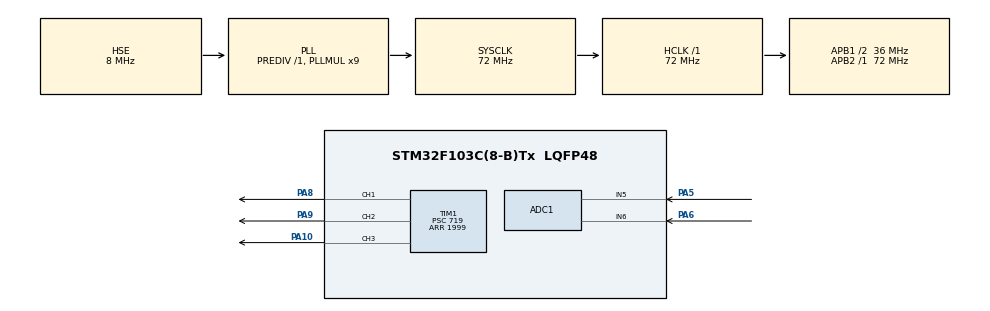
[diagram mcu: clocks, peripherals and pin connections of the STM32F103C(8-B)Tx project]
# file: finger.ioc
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ADC1.Channel-0\#ChannelRegularConversion=ADC_CHANNEL_5
ADC1.Channel-1\#ChannelRegularConversion=ADC_CHANNEL_6
ADC1.ContinuousConvMode=ENABLE
ADC1.NbrOfConversion=2
ADC1.NbrOfConversionFlag=1
ADC1.Rank-0\#ChannelRegularConversion=1
ADC1.Rank-1\#ChannelRegularConversion=2
ADC1.SamplingTime-0\#ChannelRegularConversion=ADC_SAMPLETIME_13CYCLES_5
ADC1.SamplingTime-1\#ChannelRegularConversion=ADC_SAMPLETIME_13CYCLES_5
ADC1.master=1
Dma.ADC1.0.Direction=DMA_PERIPH_TO_MEMORY
Dma.ADC1.0.Instance=DMA1_Channel1
Dma.ADC1.0.MemDataAlignment=DMA_MDATAALIGN_HALFWORD
Dma.ADC1.0.MemInc=DMA_MINC_ENABLE
Dma.ADC1.0.Mode=DMA_CIRCULAR
Dma.ADC1.0.PeriphDataAlignment=DMA_PDATAALIGN_HALFWORD
Dma.ADC1.0.PeriphInc=DMA_PINC_DISABLE
Dma.ADC1.0.Priority=DMA_PRIORITY_LOW
Dma.Request0=ADC1
Mcu.Family=STM32F1
Mcu.Name=STM32F103C(8-B)Tx
Mcu.Package=LQFP48
NVIC.DMA1_Channel1_IRQn=true\:0\:0\:false\:false\:true\:false\:true\:true
NVIC.PriorityGroup=NVIC_PRIORITYGROUP_4
PA10.Signal=S_TIM1_CH3
PA13.Mode=Serial_Wire
PA13.Signal=SYS_JTMS-SWDIO
PA14.Mode=Serial_Wire
PA14.Signal=SYS_JTCK-SWCLK
PA5.Signal=ADCx_IN5
PA6.Signal=ADCx_IN6
PA8.Signal=S_TIM1_CH1
PA9.Signal=S_TIM1_CH2
PC14-OSC32_IN.Mode=LSE-External-Oscillator
PC14-OSC32_IN.Signal=RCC_OSC32_IN
PC15-OSC32_OUT.Mode=LSE-External-Oscillator
PC15-OSC32_OUT.Signal=RCC_OSC32_OUT
PD0-OSC_IN.Mode=HSE-External-Oscillator
PD0-OSC_IN.Signal=RCC_OSC_IN
PD1-OSC_OUT.Mode=HSE-External-Oscillator
PD1-OSC_OUT.Signal=RCC_OSC_OUT
ProjectManager.HeapSize=0x200
ProjectManager.StackSize=0x400
ProjectManager.TargetToolchain=STM32CubeIDE
RCC.ADCPresc=RCC_ADCPCLK2_DIV6
RCC.AHBFreq_Value=72000000
RCC.APB1CLKDivider=RCC_HCLK_DIV2
RCC.APB1Freq_Value=36000000
RCC.APB1TimFreq_Value=72000000
RCC.APB2Freq_Value=72000000
RCC.APB2TimFreq_Value=72000000
RCC.HCLKFreq_Value=72000000
RCC.PLLMUL=RCC_PLL_MUL9
RCC.PLLSourceVirtual=RCC_PLLSOURCE_HSE
RCC.SYSCLKFreq_VALUE=72000000
RCC.SYSCLKSource=RCC_SYSCLKSOURCE_PLLCLK
RCC.USBFreq_Value=72000000
SH.ADCx_IN5.0=ADC1_IN5,IN5
SH.ADCx_IN6.0=ADC1_IN6,IN6
SH.S_TIM1_CH1.0=TIM1_CH1,PWM Generation1 CH1
SH.S_TIM1_CH2.0=TIM1_CH2,PWM Generation2 CH2
SH.S_TIM1_CH3.0=TIM1_CH3,PWM Generation3 CH3
TIM1.Channel-PWM\ Generation1\ CH1=TIM_CHANNEL_1
TIM1.Channel-PWM\ Generation2\ CH2=TIM_CHANNEL_2
TIM1.Channel-PWM\ Generation3\ CH3=TIM_CHANNEL_3
TIM1.Period=1999
TIM1.Prescaler=719
board=custom

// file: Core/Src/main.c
/* USER CODE BEGIN Header */
/**
  ******************************************************************************
  * @file           : main.c
  * @brief          : Main program body
  ******************************************************************************
  * @attention
  *
  * Copyright (c) 2025 STMicroelectronics.
  * All rights reserved.
  *
  * This software is licensed under terms that can be found in the LICENSE file
  * in the root directory of this software component.
  * If no LICENSE file comes with this software, it is provided AS-IS.
  *
  ******************************************************************************
  */
/* USER CODE END Header */
#include "main.h"
#include "adc.h"
#include "dma.h"
#include "tim.h"
#include "gpio.h"

/* USER CODE BEGIN Includes */
#include "servo.h"
#include "adc_to_duty.h"
#include "stdint.h"
/* USER CODE END Includes */

/* USER CODE BEGIN PV */
extern TIM_HandleTypeDef htim1;
uint16_t values[2];
int d1=0, d2=0;
/* USER CODE END PV */

void SystemClock_Config(void);

int main(void)
{

  /* MCU Configuration--------------------------------------------------------*/

  /* Reset of all peripherals, Initializes the Flash interface and the Systick. */
  HAL_Init();

  /* Configure the system clock */
  SystemClock_Config();

  /* Initialize all configured peripherals */
  MX_GPIO_Init();
  MX_DMA_Init();
  MX_TIM1_Init();
  MX_ADC1_Init();
  /* USER CODE BEGIN 2 */
  HAL_TIM_PWM_Start(&htim1, TIM_CHANNEL_ALL);

  HAL_ADCEx_Calibration_Start(&hadc1);
  HAL_ADC_Start_DMA(&hadc1, (uint32_t*)values, sizeof(values)/sizeof(uint16_t));

  /* USER CODE END 2 */

  /* Infinite loop */
  /* USER CODE BEGIN WHILE */
  while (1)
  {
	  d1 = Transform(values[0]);
	  d2 = Transform(values[1]);
	  Load(d1, d2);
    /* USER CODE END WHILE */

  }
}

void SystemClock_Config(void)
{
  RCC_OscInitTypeDef RCC_OscInitStruct = {0};
  RCC_ClkInitTypeDef RCC_ClkInitStruct = {0};
  RCC_PeriphCLKInitTypeDef PeriphClkInit = {0};

  /** Initializes the RCC Oscillators according to the specified parameters
  * in the RCC_OscInitTypeDef structure.
  */
  RCC_OscInitStruct.OscillatorType = RCC_OSCILLATORTYPE_HSE;
  RCC_OscInitStruct.HSEState = RCC_HSE_ON;
  RCC_OscInitStruct.HSEPredivValue = RCC_HSE_PREDIV_DIV1;
  RCC_OscInitStruct.HSIState = RCC_HSI_ON;
  RCC_OscInitStruct.PLL.PLLState = RCC_PLL_ON;
  RCC_OscInitStruct.PLL.PLLSource = RCC_PLLSOURCE_HSE;
  RCC_OscInitStruct.PLL.PLLMUL = RCC_PLL_MUL9;
  if (HAL_RCC_OscConfig(&RCC_OscInitStruct) != HAL_OK)
  {
    Error_Handler();
  }

  /** Initializes the CPU, AHB and APB buses clocks
  */
  RCC_ClkInitStruct.ClockType = RCC_CLOCKTYPE_HCLK|RCC_CLOCKTYPE_SYSCLK
                              |RCC_CLOCKTYPE_PCLK1|RCC_CLOCKTYPE_PCLK2;
  RCC_ClkInitStruct.SYSCLKSource = RCC_SYSCLKSOURCE_PLLCLK;
  RCC_ClkInitStruct.AHBCLKDivider = RCC_SYSCLK_DIV1;
  RCC_ClkInitStruct.APB1CLKDivider = RCC_HCLK_DIV2;
  RCC_ClkInitStruct.APB2CLKDivider = RCC_HCLK_DIV1;

  if (HAL_RCC_ClockConfig(&RCC_ClkInitStruct, FLASH_LATENCY_2) != HAL_OK)
  {
    Error_Handler();
  }
  PeriphClkInit.PeriphClockSelection = RCC_PERIPHCLK_ADC;
  PeriphClkInit.AdcClockSelection = RCC_ADCPCLK2_DIV6;
  if (HAL_RCCEx_PeriphCLKConfig(&PeriphClkInit) != HAL_OK)
  {
    Error_Handler();
  }
}

void Error_Handler(void)
{
  __disable_irq();
  while (1)
  {
  }
}
